# STM32WL5X_CM0P register map
File version: 2.1
CPU: CM0 r0p1, little endian, MPU, no FPU, 4 interrupt priority bits
Registers are 32-bit, read-write, reset 0x0 unless marked. A register's access mark holds for its fields unless they carry their own. Offsets are from the block's base; [hi:lo] are bit positions; {n}, {i} and the like mark numbered series; 'fields as' and 'values as' point back to an identical list.

## EXTI — External interrupt/event controller
Base 0x58000800
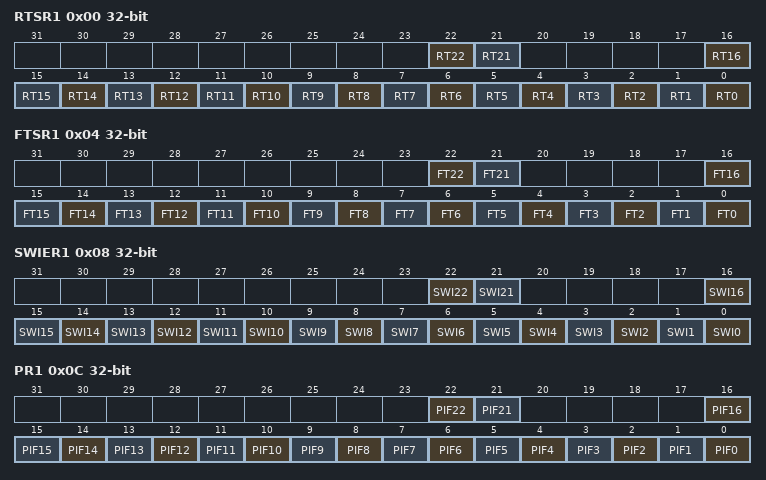
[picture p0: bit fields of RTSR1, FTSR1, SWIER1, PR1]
0x00 RTSR1 — EXTI rising trigger selection register
  [all] fields
    0=Disabled (Rising edge trigger is disabled); 1=Enabled (Rising edge trigger is enabled)
  [22] RT22 — rising trigger event configuration bit of configurable event input 22 Note: The configurable event inputs are edge triggered. No glitch must be generated on these inputs. If a rising edge on the configurable event input occurs while writing to the register, the associated pending bit is not set. Note: Rising and falling edge triggers can be set for the same configurable event input. In this case, both edges generate a trigger.
  [21] RT21 — rising trigger event configuration bit of configurable event input 21
  [n] RT{n} (n=0..16) — rising trigger event configuration bit of configurable event input {n}
0x04 FTSR1 — EXTI falling trigger selection register
  [all] fields
    0=Disabled (Falling edge trigger is disabled); 1=Enabled (Falling edge trigger is enabled)
  [22] FT22 — falling trigger event configuration bit of configurable event input 22 Note: The configurable event inputs are edge triggered. No glitch must be generated on these inputs. If a falling edge on the configurable event input occurs while writing to the register, the associated pending bit is not set. Note: Rising and falling edge triggers can be set for the same configurable event input. In this case, both edges generate a trigger.
  [21] FT21 — falling trigger event configuration bit of configurable event input 21
  [n] FT{n} (n=0..16) — falling trigger event configuration bit of configurable event input {n}
0x08 SWIER1 — EXTI software interrupt event register
  [all] fields
    on write: 1=Pend (Generates an interrupt request)
  [22] SWI22 — Software interrupt on line 22 A software interrupt is generated independently from the setting in EXTI_RTSR and EXTI_FTSR. This bit always returns 0 when read. This bit is automatically cleared by hardware.
  [21] SWI21 — Software interrupt on line 21
  [n] SWI{n} (n=0..16) — Software interrupt on line {n}
0x0C PR1 — EXTI pending register
  [all] fields
    on read: 0=NotPending (No trigger request occurred); 1=Pending (Selected trigger request occurred) | on write: 1=Clears pending bit
  [22] PIF22 write-1-clears — pending bit on event input 22 These bits are set when the selected edge event or an EXTI_SWIER software trigger arrives on the configurable event line. This bit is cleared by writing 1 to it.
  [21] PIF21 write-1-clears — pending bit on event input 21
  [n] PIF{n} write-1-clears (n=0..16) — pending bit on event input {n}
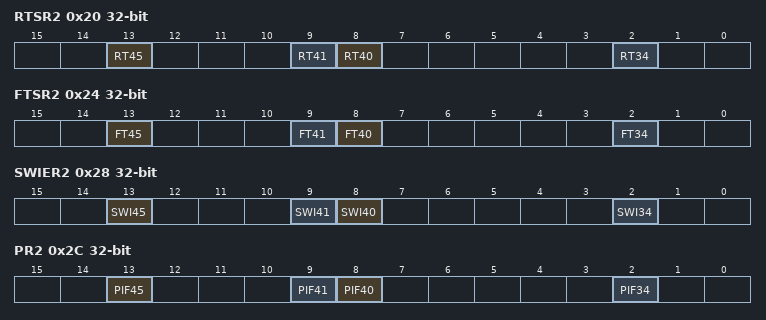
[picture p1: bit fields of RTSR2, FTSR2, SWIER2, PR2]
0x20 RTSR2 — EXTI rising trigger selection register
  [all] fields
    values as the fields of RTSR1
  [13] RT45 — rising trigger event configuration bit of configurable event input 45 Note: The configurable event inputs are edge triggered. No glitch must be generated on these inputs. If a rising edge on the configurable event input occurs while writing to the register, the associated pending bit is not set. Note: Rising and falling edge triggers can be set for the same configurable event input. In this case, both edges generate a trigger.
  [9] RT41 — rising trigger event configuration bit of configurable event input 41
  [8] RT40 — rising trigger event configuration bit of configurable event input 40
  [2] RT34 — rising trigger event configuration bit of configurable event input 34
0x24 FTSR2 — EXTI falling trigger selection register
  [all] fields
    values as the fields of FTSR1
  [13] FT45 — falling trigger event configuration bit of configurable event input 45 Note: The configurable event inputs are edge triggered. No glitch must be generated on these inputs. If a falling edge on the configurable event input occurs while writing to the register, the associated pending bit is not set. Note: Rising and falling edge triggers can be set for the same configurable event input. In this case, both edges generate a trigger.
  [9] FT41 — falling trigger event configuration bit of configurable event input 41
  [8] FT40 — falling trigger event configuration bit of configurable event input 40
  [2] FT34 — falling trigger event configuration bit of configurable event input 34
0x28 SWIER2 — EXTI software interrupt event register
  [all] fields
    on write: 1=Pend (Generates an interrupt request)
  [13] SWI45 — software interrupt on event 45 A software interrupt is generated independently from the setting in EXTI_RTSR and EXTI_FTSR. This bit always returns 0 when read. This bit is automatically cleared by hardware.
  [9] SWI41 — software interrupt on event 41
  [8] SWI40 — software interrupt on event 40
  [2] SWI34 — software interrupt on event 34
0x2C PR2 — EXTI pending register
  [all] fields
    values as the fields of PR1
  [13] PIF45 write-1-clears — pending bit on event input 45 These bits are set when the selected edge event or an EXTI_SWIER software trigger arrives on the configurable event line. This bit is cleared by writing 1 to it.
  [9] PIF41 write-1-clears — pending bit on event input 41
  [8] PIF40 write-1-clears — pending bit on event input 40
  [2] PIF34 write-1-clears — pending bit on event input 34
0x80 C1IMR1 — EXTI interrupt mask register
  [31:0] IM — Wake-up with interrupt mask on event input x For each bit of this field:
    0=Masked (Interrupt request line is masked); 1=Unmasked (Interrupt request line is unmasked)
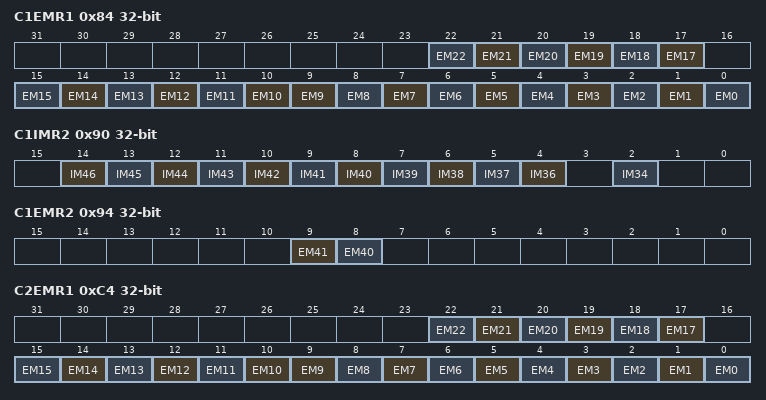
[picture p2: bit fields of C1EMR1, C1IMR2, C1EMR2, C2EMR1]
0x84 C1EMR1 — EXTI event mask register
  [all] fields
    0=Masked (Event request line is masked); 1=Unmasked (Event request line is unmasked)
  [n] EM{n} (n=17..22) — Wake-up with event generation mask on event input {n}
  [n] EM{n} (n=10..15) — Wake-up with event generation mask on event input {n}
  [9] EM9 — Wake-up with event generation mask on event input 19
  [n] EM{n} (n=0..8) — Wake-up with event generation mask on event input {n}
0x90 C1IMR2 — EXTI interrupt mask register
  [all] fields
    values as C1IMR1.IM
  [n-32] IM{n} (n=36..46) — Wake-up with interrupt mask on event input {n}
  [2] IM34 — Wake-up with interrupt mask on event input 34
0x94 C1EMR2 — EXTI event mask register
  [9] EM41 — Wake-up with event generation mask on event input 41
    values as the fields of C1EMR1
  [8] EM40 — Wake-up with event generation mask on event input 40
    values as the fields of C1EMR1
0xC0 C2IMR1 — EXTI interrupt mask register
  fields as C1IMR1
0xC4 C2EMR1 — EXTI event mask register
  fields as C1EMR1
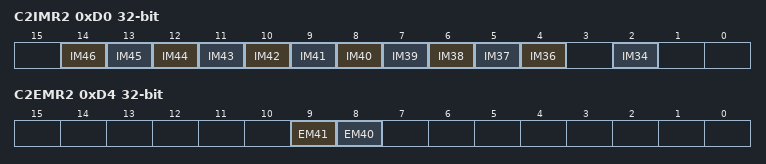
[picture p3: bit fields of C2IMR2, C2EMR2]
0xD0 C2IMR2 — EXTI interrupt mask register
  fields as C1IMR2
0xD4 C2EMR2 — EXTI event mask register
  fields as C1EMR2
